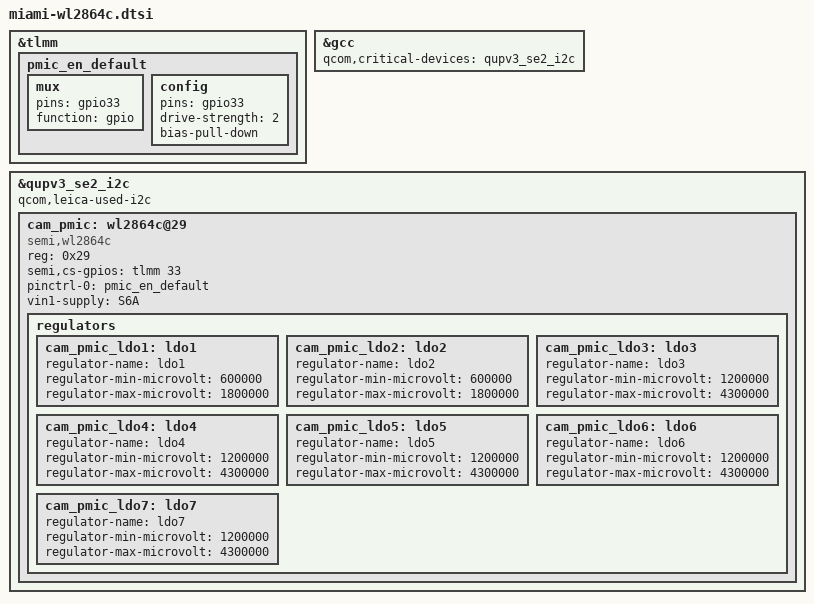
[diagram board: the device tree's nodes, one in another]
&tlmm{
	pmic_en_default: pmic_en_default {
		mux {
			pins = "gpio33";
			function = "gpio";
		};
		config {
			pins = "gpio33";
			drive-strength = <2>;
			bias-pull-down;
		};
	};
};

&gcc {
	qcom,critical-devices = <&qupv3_se2_i2c>;
};

&qupv3_se2_i2c {
	status = "ok";
	qcom,leica-used-i2c;
	cam_pmic: wl2864c@29{
		compatible = "semi,wl2864c";
		reg = <0x29>;
		semi,cs-gpios = <&tlmm 33 0>;
		pinctrl-names = "default";
		pinctrl-0 = <&pmic_en_default>;
		vin1-supply = <&S6A>;

		regulators {
			cam_pmic_ldo1: ldo1 {
				regulator-name = "ldo1";
				regulator-min-microvolt = <600000>;
				regulator-max-microvolt = <1800000>;
			};

			cam_pmic_ldo2: ldo2 {
				regulator-name = "ldo2";
				regulator-min-microvolt = <600000>;
				regulator-max-microvolt = <1800000>;
			};

			cam_pmic_ldo3: ldo3 {
				regulator-name = "ldo3";
				regulator-min-microvolt = <1200000>;
				regulator-max-microvolt = <4300000>;
			};

			cam_pmic_ldo4: ldo4 {
				regulator-name = "ldo4";
				regulator-min-microvolt = <1200000>;
				regulator-max-microvolt = <4300000>;
			};

			cam_pmic_ldo5: ldo5 {
				regulator-name = "ldo5";
				regulator-min-microvolt = <1200000>;
				regulator-max-microvolt = <4300000>;
			};

			cam_pmic_ldo6: ldo6 {
				regulator-name = "ldo6";
				regulator-min-microvolt = <1200000>;
				regulator-max-microvolt = <4300000>;
			};

			cam_pmic_ldo7: ldo7 {
				regulator-name = "ldo7";
				regulator-min-microvolt = <1200000>;
				regulator-max-microvolt = <4300000>;
			};
		};
	};
};
